AUTOSAR XML (schema 4-2-2)
package /Components
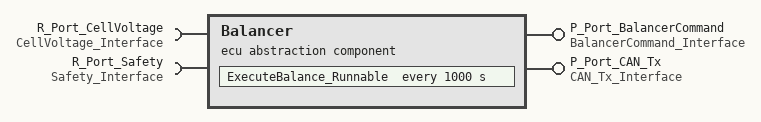
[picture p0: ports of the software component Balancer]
  ecu abstraction sw component type Balancer
    provide port P_Port_BalancerCommand: provided-interface=BalancerCommand_Interface
    provide port P_Port_CAN_Tx: provided-interface=CAN_Tx_Interface
    require port R_Port_CellVoltage: required-interface=CellVoltage_Interface
    require port R_Port_Safety: required-interface=Safety_Interface
    behavior Balancer_Behavior
      external trigger occurred event Balance_Command_Received: start-on-event=ExecuteBalance_Runnable
      timing event Balance_Periodic: start-on-event=ExecuteBalance_Runnable, period=1000
      runnable ExecuteBalance_Runnable: minimum-start-interval=1000, symbol=Balancer_ExecuteBalance
        data-receive-point-by-arguments:
          access Read_CellVoltageSummary: accessed-variable=R_Port_CellVoltage.cellVoltageSummary
          access Read_SafetyLimits: accessed-variable=R_Port_Safety.safetyLimits
        data-write-access:
          access Write_CAN_Status: accessed-variable=P_Port_CAN_Tx.CAN_Frame
